# coredebug register map
Vendor: Texas Instruments
Peripheral module from a debugger description file (folder MSP432).
Registers are 32-bit, read-write, no defined reset value unless marked. A register's access mark holds for its fields unless they carry their own. Offsets are as the file gives them; lines under a group give offsets from that group; [hi:lo] are bit positions; {n}, {i} and the like mark numbered series; 'fields as' and 'values as' point back to an identical list; <NAME> marks a mode.

## COREDEBUG
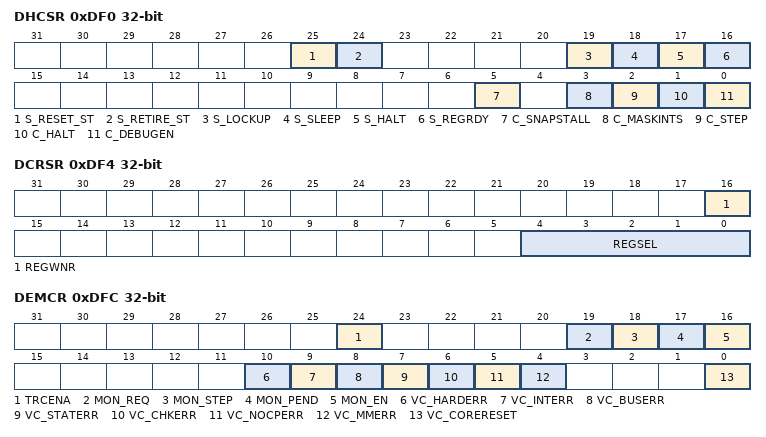
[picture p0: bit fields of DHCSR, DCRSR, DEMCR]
0xDF0 DHCSR — Debug Halting Control and Status Register
  [25] S_RESET_ST — Indicates that the core has been reset, or is now being reset,
  [24] S_RETIRE_ST — Indicates that an instruction has completed since last read
  [19] S_LOCKUP — Reads as one if the core is running (not halted) and a lockup c
  [18] S_SLEEP — Indicates that the core is sleeping (WFI, WFE, or SLEEP-ON-EXIT
  [17] S_HALT — The core is in debug state when S_HALT is set.
  [16] S_REGRDY — Register Read/Write on the Debug Core Register Selector registe
  [5] C_SNAPSTALL — If the core is stalled on a load/store operation the stall ceas
  [3] C_MASKINTS — Mask interrupts when stepping or running in halted debug
  [2] C_STEP — Steps the core in halted debug
  [1] C_HALT — Halts the core
  [0] C_DEBUGEN — Enables debug
0xDF4 DCRSR — Deubg Core Register Selector Register
  [16] REGWNR — Write = 1, Read = 0
  [4:0] REGSEL — Register select
    0=REGSEL__0 (R0); 0=REGSEL__0 (R11); {v}=REGSEL__{v} (R{v}) (v=1..10); 12=REGSEL__12 (R12); 13=REGSEL__13 (Current SP); 14=REGSEL__14 (LR); 15=REGSEL__15 (DebugReturnAddress); 16=REGSEL__16 (xPSR/flags, execution state information, and exception number); 17=REGSEL__17 (MSP (Main SP)); 18=REGSEL__18 (PSP (Process SP)); 20=REGSEL__20 (CONTROL bits [31:24], FAULTMASK bits [23:16], BASEPRI bits [15:)
0xDF8 DCRDR access not given — Debug Core Register Data Register
0xDFC DEMCR — Debug Exception and Monitor Control Register
  [24] TRCENA — This bit must be set to 1 to enable use of the trace and debug
  [19] MON_REQ — This enables the monitor to identify how it wakes up
    0=MON_REQ__0 (woken up by debug exception.); 1=MON_REQ__1 (woken up by MON_PEND)
  [18] MON_STEP — When MON_EN = 1, this steps the core
  [17] MON_PEND — Pend the monitor to activate when priority permits
  [16] MON_EN — Enable the debug monitor
  [10] VC_HARDERR — Debug trap on Hard Fault.
  [9] VC_INTERR — Debug Trap on interrupt/exception service errors
  [8] VC_BUSERR — Debug Trap on normal Bus error.
  [7] VC_STATERR — Debug trap on Usage Fault state errors.
  [6] VC_CHKERR — Debug trap on Usage Fault enabled checking errors.
  [5] VC_NOCPERR — Debug trap on Usage Fault access to Coprocessor that is not pre
  [4] VC_MMERR — Debug trap on Memory Management faults.
  [0] VC_CORERESET — Reset Vector Catch. Halt running system if Core reset occurs.
